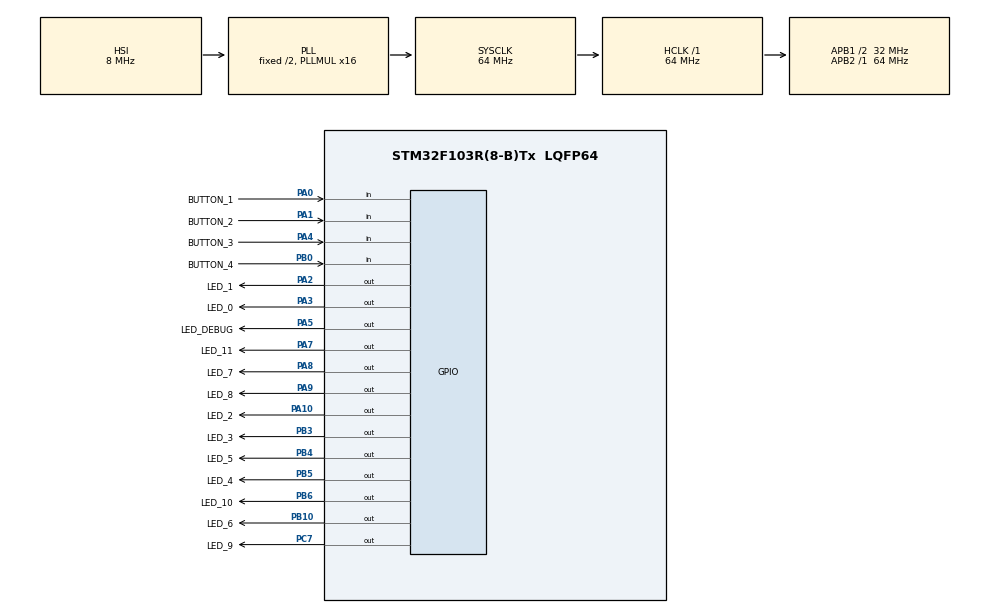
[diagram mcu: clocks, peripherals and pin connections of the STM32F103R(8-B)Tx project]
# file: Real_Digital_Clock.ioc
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Mcu.Family=STM32F1
Mcu.Name=STM32F103R(8-B)Tx
Mcu.Package=LQFP64
NVIC.PriorityGroup=NVIC_PRIORITYGROUP_4
NVIC.TIM2_IRQn=true\:0\:0\:false\:false\:true\:true\:true\:true
PA0-WKUP.GPIO_Label=BUTTON_1
PA0-WKUP.GPIO_PuPd=GPIO_PULLUP
PA0-WKUP.Signal=GPIO_Input
PA1.GPIO_Label=BUTTON_2
PA1.GPIO_PuPd=GPIO_PULLUP
PA1.Signal=GPIO_Input
PA10.GPIO_Label=LED_2
PA10.Signal=GPIO_Output
PA13.Mode=Serial_Wire
PA13.Signal=SYS_JTMS-SWDIO
PA14.Mode=Serial_Wire
PA14.Signal=SYS_JTCK-SWCLK
PA2.GPIO_Label=LED_1
PA2.Signal=GPIO_Output
PA3.GPIO_Label=LED_0
PA3.Signal=GPIO_Output
PA4.GPIO_Label=BUTTON_3
PA4.GPIO_PuPd=GPIO_PULLUP
PA4.Signal=GPIO_Input
PA5.GPIO_Label=LED_DEBUG
PA5.Signal=GPIO_Output
PA7.GPIO_Label=LED_11
PA7.Signal=GPIO_Output
PA8.GPIO_Label=LED_7
PA8.Signal=GPIO_Output
PA9.GPIO_Label=LED_8
PA9.Signal=GPIO_Output
PB0.GPIO_Label=BUTTON_4
PB0.GPIO_PuPd=GPIO_PULLUP
PB0.Signal=GPIO_Input
PB10.GPIO_Label=LED_6
PB10.Signal=GPIO_Output
PB3.GPIO_Label=LED_3
PB3.Signal=GPIO_Output
PB4.GPIO_Label=LED_5
PB4.Signal=GPIO_Output
PB5.GPIO_Label=LED_4
PB5.Signal=GPIO_Output
PB6.GPIO_Label=LED_10
PB6.Signal=GPIO_Output
PC7.GPIO_Label=LED_9
PC7.Signal=GPIO_Output
ProjectManager.HeapSize=0x200
ProjectManager.StackSize=0x400
ProjectManager.TargetToolchain=STM32CubeIDE
RCC.AHBFreq_Value=64000000
RCC.APB1CLKDivider=RCC_HCLK_DIV2
RCC.APB1Freq_Value=32000000
RCC.APB1TimFreq_Value=64000000
RCC.APB2Freq_Value=64000000
RCC.APB2TimFreq_Value=64000000
RCC.HCLKFreq_Value=64000000
RCC.PLLMUL=RCC_PLL_MUL16
RCC.SYSCLKFreq_VALUE=64000000
RCC.SYSCLKSource=RCC_SYSCLKSOURCE_PLLCLK
RCC.USBFreq_Value=64000000
TIM2.Period=624
TIM2.Prescaler=1023
VP_TIM2_VS_ClockSourceINT.Mode=Internal
board=custom

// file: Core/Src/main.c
/* USER CODE BEGIN Header */
/**
  ******************************************************************************
  * @file           : main.c
  * @brief          : Main program body
  ******************************************************************************
  * @attention
  *
  * Copyright (c) 2024 STMicroelectronics.
  * All rights reserved.
  *
  * This software is licensed under terms that can be found in the LICENSE file
  * in the root directory of this software component.
  * If no LICENSE file comes with this software, it is provided AS-IS.
  *
  ******************************************************************************
  */
/* USER CODE END Header */
#include "main.h"

/* USER CODE BEGIN Includes */
#include "software_timer.h"
#include "button.h"
#include "fsm_clock.h"
#include "clock_display.h"
/* USER CODE END Includes */

TIM_HandleTypeDef htim2;

void SystemClock_Config(void);
static void MX_GPIO_Init(void);
static void MX_TIM2_Init(void);

int main(void)
{

  /* MCU Configuration--------------------------------------------------------*/

  /* Reset of all peripherals, Initializes the Flash interface and the Systick. */
  HAL_Init();

  /* Configure the system clock */
  SystemClock_Config();

  /* Initialize all configured peripherals */
  MX_GPIO_Init();
  MX_TIM2_Init();
  /* USER CODE BEGIN 2 */
  HAL_TIM_Base_Start_IT(&htim2);
  /* USER CODE END 2 */
  initButton();
  initDebug();
  /* Infinite loop */
  /* USER CODE BEGIN WHILE */
  while (1)
  {
	  fsm_clock();
	  auto_debug();
    /* USER CODE END WHILE */

  }
}

void SystemClock_Config(void)
{
  RCC_OscInitTypeDef RCC_OscInitStruct = {0};
  RCC_ClkInitTypeDef RCC_ClkInitStruct = {0};

  /** Initializes the RCC Oscillators according to the specified parameters
  * in the RCC_OscInitTypeDef structure.
  */
  RCC_OscInitStruct.OscillatorType = RCC_OSCILLATORTYPE_HSI;
  RCC_OscInitStruct.HSIState = RCC_HSI_ON;
  RCC_OscInitStruct.HSICalibrationValue = RCC_HSICALIBRATION_DEFAULT;
  RCC_OscInitStruct.PLL.PLLState = RCC_PLL_ON;
  RCC_OscInitStruct.PLL.PLLSource = RCC_PLLSOURCE_HSI_DIV2;
  RCC_OscInitStruct.PLL.PLLMUL = RCC_PLL_MUL16;
  if (HAL_RCC_OscConfig(&RCC_OscInitStruct) != HAL_OK)
  {
    Error_Handler();
  }

  /** Initializes the CPU, AHB and APB buses clocks
  */
  RCC_ClkInitStruct.ClockType = RCC_CLOCKTYPE_HCLK|RCC_CLOCKTYPE_SYSCLK
                              |RCC_CLOCKTYPE_PCLK1|RCC_CLOCKTYPE_PCLK2;
  RCC_ClkInitStruct.SYSCLKSource = RCC_SYSCLKSOURCE_PLLCLK;
  RCC_ClkInitStruct.AHBCLKDivider = RCC_SYSCLK_DIV1;
  RCC_ClkInitStruct.APB1CLKDivider = RCC_HCLK_DIV2;
  RCC_ClkInitStruct.APB2CLKDivider = RCC_HCLK_DIV1;

  if (HAL_RCC_ClockConfig(&RCC_ClkInitStruct, FLASH_LATENCY_2) != HAL_OK)
  {
    Error_Handler();
  }
}

static void MX_TIM2_Init(void)
{

  TIM_ClockConfigTypeDef sClockSourceConfig = {0};
  TIM_MasterConfigTypeDef sMasterConfig = {0};

  htim2.Instance = TIM2;
  htim2.Init.Prescaler = 1023;
  htim2.Init.CounterMode = TIM_COUNTERMODE_UP;
  htim2.Init.Period = 624;
  htim2.Init.ClockDivision = TIM_CLOCKDIVISION_DIV1;
  htim2.Init.AutoReloadPreload = TIM_AUTORELOAD_PRELOAD_DISABLE;
  if (HAL_TIM_Base_Init(&htim2) != HAL_OK)
  {
    Error_Handler();
  }
  sClockSourceConfig.ClockSource = TIM_CLOCKSOURCE_INTERNAL;
  if (HAL_TIM_ConfigClockSource(&htim2, &sClockSourceConfig) != HAL_OK)
  {
    Error_Handler();
  }
  sMasterConfig.MasterOutputTrigger = TIM_TRGO_RESET;
  sMasterConfig.MasterSlaveMode = TIM_MASTERSLAVEMODE_DISABLE;
  if (HAL_TIMEx_MasterConfigSynchronization(&htim2, &sMasterConfig) != HAL_OK)
  {
    Error_Handler();
  }

}

static void MX_GPIO_Init(void)
{
  GPIO_InitTypeDef GPIO_InitStruct = {0};

  /* GPIO Ports Clock Enable */
  __HAL_RCC_GPIOA_CLK_ENABLE();
  __HAL_RCC_GPIOB_CLK_ENABLE();
  __HAL_RCC_GPIOC_CLK_ENABLE();

  /*Configure GPIO pin Output Level */
  HAL_GPIO_WritePin(GPIOA, LED_1_Pin|LED_0_Pin|LED_DEBUG_Pin|LED_11_Pin
                          |LED_7_Pin|LED_8_Pin|LED_2_Pin, GPIO_PIN_RESET);

  /*Configure GPIO pin Output Level */
  HAL_GPIO_WritePin(GPIOB, LED_6_Pin|LED_3_Pin|LED_5_Pin|LED_4_Pin
                          |LED_10_Pin, GPIO_PIN_RESET);

  /*Configure GPIO pin Output Level */
  HAL_GPIO_WritePin(LED_9_GPIO_Port, LED_9_Pin, GPIO_PIN_RESET);

  /*Configure GPIO pins : BUTTON_1_Pin BUTTON_2_Pin BUTTON_3_Pin */
  GPIO_InitStruct.Pin = BUTTON_1_Pin|BUTTON_2_Pin|BUTTON_3_Pin;
  GPIO_InitStruct.Mode = GPIO_MODE_INPUT;
  GPIO_InitStruct.Pull = GPIO_PULLUP;
  HAL_GPIO_Init(GPIOA, &GPIO_InitStruct);

  /*Configure GPIO pins : LED_1_Pin LED_0_Pin LED_DEBUG_Pin LED_11_Pin
                           LED_7_Pin LED_8_Pin LED_2_Pin */
  GPIO_InitStruct.Pin = LED_1_Pin|LED_0_Pin|LED_DEBUG_Pin|LED_11_Pin
                          |LED_7_Pin|LED_8_Pin|LED_2_Pin;
  GPIO_InitStruct.Mode = GPIO_MODE_OUTPUT_PP;
  GPIO_InitStruct.Pull = GPIO_NOPULL;
  GPIO_InitStruct.Speed = GPIO_SPEED_FREQ_LOW;
  HAL_GPIO_Init(GPIOA, &GPIO_InitStruct);

  /*Configure GPIO pin : BUTTON_4_Pin */
  GPIO_InitStruct.Pin = BUTTON_4_Pin;
  GPIO_InitStruct.Mode = GPIO_MODE_INPUT;
  GPIO_InitStruct.Pull = GPIO_PULLUP;
  HAL_GPIO_Init(BUTTON_4_GPIO_Port, &GPIO_InitStruct);

  /*Configure GPIO pins : LED_6_Pin LED_3_Pin LED_5_Pin LED_4_Pin
                           LED_10_Pin */
  GPIO_InitStruct.Pin = LED_6_Pin|LED_3_Pin|LED_5_Pin|LED_4_Pin
                          |LED_10_Pin;
  GPIO_InitStruct.Mode = GPIO_MODE_OUTPUT_PP;
  GPIO_InitStruct.Pull = GPIO_NOPULL;
  GPIO_InitStruct.Speed = GPIO_SPEED_FREQ_LOW;
  HAL_GPIO_Init(GPIOB, &GPIO_InitStruct);

  /*Configure GPIO pin : LED_9_Pin */
  GPIO_InitStruct.Pin = LED_9_Pin;
  GPIO_InitStruct.Mode = GPIO_MODE_OUTPUT_PP;
  GPIO_InitStruct.Pull = GPIO_NOPULL;
  GPIO_InitStruct.Speed = GPIO_SPEED_FREQ_LOW;
  HAL_GPIO_Init(LED_9_GPIO_Port, &GPIO_InitStruct);

}

/* USER CODE BEGIN 4 */
void HAL_TIM_PeriodElapsedCallback(TIM_HandleTypeDef *htim)
{
	button_reading();
	timerRun();
}
/* USER CODE END 4 */

void Error_Handler(void)
{
  __disable_irq();
  while (1)
  {
  }
}
